# nRF54h20_secure register map
Vendor: Nordic Semiconductor; Series: nRF54h; File version: 1
CPU: CM33 r0p4, little endian, MPU, no FPU, 3 interrupt priority bits, 480 interrupts, 8 SAU regions
Registers are 32-bit, read-write, reset 0x0 unless marked. A register's access mark holds for its fields unless they carry their own. Offsets are from the block's base; [hi:lo] are bit positions; lines under a group give offsets from that group; {n}, {i} and the like mark numbered series; 'fields as' and 'values as' point back to an identical list.

## GLOBAL_UARTE120_NS — UART with EasyDMA 0
Base 0x4F8E6000; alternate view of GLOBAL_SPIM120_NS
Same registers: GLOBAL_UARTE130_NS 0x4F9A5000 (alternate view of GLOBAL_SPIM130_NS), GLOBAL_UARTE131_NS 0x4F9A6000 (alternate view of GLOBAL_SPIM131_NS), GLOBAL_UARTE132_NS 0x4F9B5000 (alternate view of GLOBAL_SPIM132_NS), GLOBAL_UARTE133_NS 0x4F9B6000 (alternate view of GLOBAL_SPIM133_NS), GLOBAL_UARTE134_NS 0x4F9C5000 (alternate view of GLOBAL_SPIM134_NS), GLOBAL_UARTE135_NS 0x4F9C6000 (alternate view of GLOBAL_SPIM135_NS), GLOBAL_UARTE136_NS 0x4F9D5000 (alternate view of GLOBAL_SPIM136_NS), GLOBAL_UARTE137_NS 0x4F9D6000 (alternate view of GLOBAL_SPIM137_NS), GLOBAL_UARTE120_S 0x5F8E6000 (alternate view of GLOBAL_SPIM120_S), GLOBAL_UARTE130_S 0x5F9A5000 (alternate view of GLOBAL_SPIM130_S), GLOBAL_UARTE131_S 0x5F9A6000 (alternate view of GLOBAL_SPIM131_S), GLOBAL_UARTE132_S 0x5F9B5000 (alternate view of GLOBAL_SPIM132_S), GLOBAL_UARTE133_S 0x5F9B6000 (alternate view of GLOBAL_SPIM133_S), GLOBAL_UARTE134_S 0x5F9C5000 (alternate view of GLOBAL_SPIM134_S), GLOBAL_UARTE135_S 0x5F9C6000 (alternate view of GLOBAL_SPIM135_S), GLOBAL_UARTE136_S 0x5F9D5000 (alternate view of GLOBAL_SPIM136_S), GLOBAL_UARTE137_S 0x5F9D6000 (alternate view of GLOBAL_SPIM137_S)
0x0C TASKS_SUSPEND wo — Suspend UART transaction
  [0] TASKS_SUSPEND
    1=Trigger task
0x10 TASKS_RESUME wo — Resume UART transaction
  [0] TASKS_RESUME
    1=Trigger task
0x1C TASKS_FLUSHRX wo — Flush RX FIFO into RX buffer
  [0] TASKS_FLUSHRX
    1=Trigger task
0x28 TASKS_DMA group — Peripheral tasks.
  0x00 RX group — Peripheral tasks.
    0x00 START wo — Starts operation using easyDMA to load the values. See peripheral description for operation using easyDMA.
      [0] START
        1=Trigger task
    0x04 STOP wo — Stops operation using easyDMA. This does not trigger an END event. After a STOP task, the easyDMA (channel) will also enter its lowest required power level.
      [0] STOP
        1=Trigger task
    {0x8+4k} ENABLEMATCH[{k}] (k=0..3) wo — Description collection: Enables the MATCH[n] event by setting the ENABLE[n] bit in the CONFIG register.
      [0] ENABLEMATCH — Enables the MATCH[n] event by setting the ENABLE[n] bit in the CONFIG register.
        1=Trigger task
    {0x18+4k} DISABLEMATCH[{k}] (k=0..3) wo — Description collection: Disables the MATCH[n] event by clearing the ENABLE[n] bit in the CONFIG register.
      [0] DISABLEMATCH — Disables the MATCH[n] event by clearing the ENABLE[n] bit in the CONFIG register.
        1=Trigger task
  0x28 TX group — Peripheral tasks.
    0x00 START wo — Starts operation using easyDMA to load the values. See peripheral description for operation using easyDMA.
      [0] START
        1=Trigger task
    0x04 STOP wo — Stops operation using easyDMA. This does not trigger an END event. After a STOP task, the easyDMA (channel) will also enter its lowest required power level.
      [0] STOP
        1=Trigger task
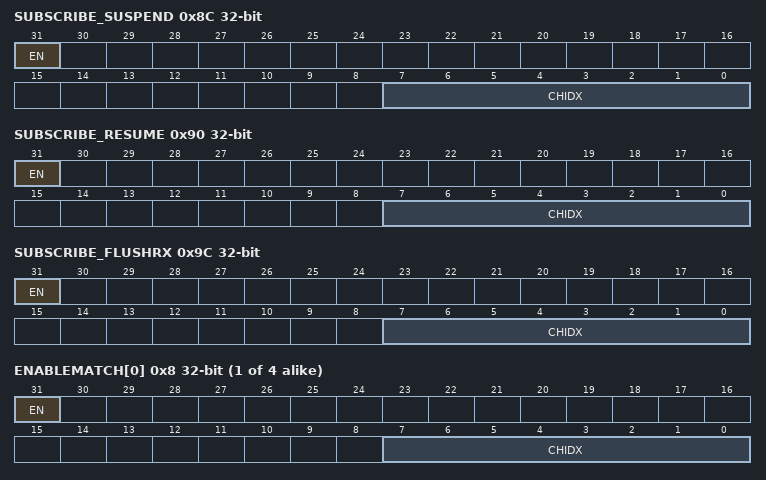
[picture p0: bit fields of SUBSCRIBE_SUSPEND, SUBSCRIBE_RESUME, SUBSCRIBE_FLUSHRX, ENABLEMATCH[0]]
0x8C SUBSCRIBE_SUSPEND — Subscribe configuration for task SUSPEND
  [31] EN
    0=Disabled (Disable subscription); 1=Enabled (Enable subscription)
  [7:0] CHIDX — DPPI channel that task SUSPEND will subscribe to
0x90 SUBSCRIBE_RESUME — Subscribe configuration for task RESUME
  [31] EN
    values as SUBSCRIBE_SUSPEND.EN
  [7:0] CHIDX — DPPI channel that task RESUME will subscribe to
0x9C SUBSCRIBE_FLUSHRX — Subscribe configuration for task FLUSHRX
  [31] EN
    values as SUBSCRIBE_SUSPEND.EN
  [7:0] CHIDX — DPPI channel that task FLUSHRX will subscribe to
0xA8 SUBSCRIBE_DMA group — Subscribe configuration for tasks
  0x00 RX group — Subscribe configuration for tasks
    0x00 START — Subscribe configuration for task START
      [31] EN
        values as SUBSCRIBE_SUSPEND.EN
      [7:0] CHIDX — DPPI channel that task START will subscribe to
    0x04 STOP — Subscribe configuration for task STOP
      [31] EN
        values as SUBSCRIBE_SUSPEND.EN
      [7:0] CHIDX — DPPI channel that task STOP will subscribe to
    {0x8+4k} ENABLEMATCH[{k}] (k=0..3) — Description collection: Subscribe configuration for task ENABLEMATCH[n]
      [31] EN
        values as SUBSCRIBE_SUSPEND.EN
      [7:0] CHIDX — DPPI channel that task ENABLEMATCH[n] will subscribe to
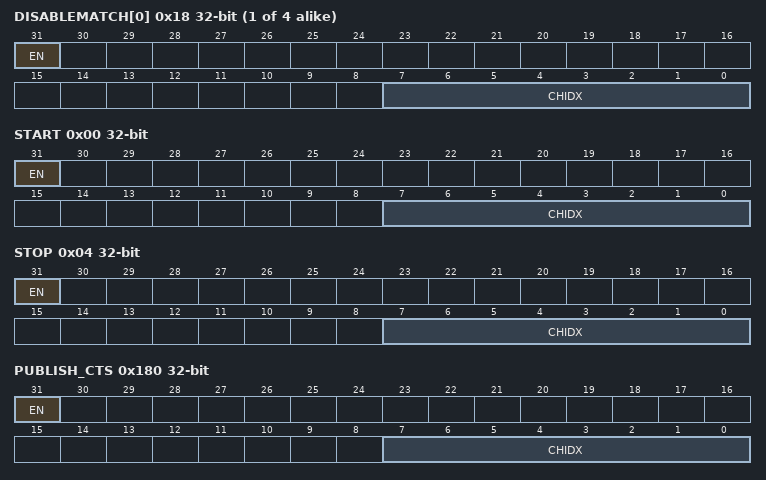
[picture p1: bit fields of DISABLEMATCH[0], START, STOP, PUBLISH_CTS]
    {0x18+4k} DISABLEMATCH[{k}] (k=0..3) — Description collection: Subscribe configuration for task DISABLEMATCH[n]
      [31] EN
        values as SUBSCRIBE_SUSPEND.EN
      [7:0] CHIDX — DPPI channel that task DISABLEMATCH[n] will subscribe to
  0x28 TX group — Subscribe configuration for tasks
    0x00 START — Subscribe configuration for task START
      fields as SUBSCRIBE_DMA.RX.START
    0x04 STOP — Subscribe configuration for task STOP
      fields as SUBSCRIBE_DMA.RX.STOP
0x100 EVENTS_CTS — CTS is activated (set low). Clear To Send.
  [0] EVENTS_CTS
    0=NotGenerated (Event not generated); 1=Generated (Event generated)
0x104 EVENTS_NCTS — CTS is deactivated (set high). Not Clear To Send.
  [0] EVENTS_NCTS
    values as EVENTS_CTS.EVENTS_CTS
0x10C EVENTS_TXDRDY — Data sent from TXD
  [0] EVENTS_TXDRDY
    values as EVENTS_CTS.EVENTS_CTS
0x110 EVENTS_RXDRDY — Data received in RXD (but potentially not yet transferred to Data RAM)
  [0] EVENTS_RXDRDY
    values as EVENTS_CTS.EVENTS_CTS
0x114 EVENTS_ERROR — Error detected
  [0] EVENTS_ERROR
    values as EVENTS_CTS.EVENTS_CTS
0x124 EVENTS_RXTO — Receiver timeout
  [0] EVENTS_RXTO
    values as EVENTS_CTS.EVENTS_CTS
0x12C EVENTS_RTS — RX FIFO has only room for four more bytes before it overflows
  [0] EVENTS_RTS
    values as EVENTS_CTS.EVENTS_CTS
0x130 EVENTS_TXSTOPPED — Transmitter stopped
  [0] EVENTS_TXSTOPPED
    values as EVENTS_CTS.EVENTS_CTS
0x14C EVENTS_DMA group — Peripheral events.
  0x00 RX group — Peripheral events.
    0x00 END — Generated after all MAXCNT bytes have been transferred Equivalent to eventDmaEnd[Channel]
      [0] END
        values as EVENTS_CTS.EVENTS_CTS
    0x04 READY — Generated when EasyDMA has buffered the .PTR and .MAXCNT registers for the channel, allowing them to be written to prepare for the next sequence.
      [0] READY
        values as EVENTS_CTS.EVENTS_CTS
    0x08 BUSERROR — An error occured during the bus transfer. This event is generated on an AHB / AXI error response.
      [0] BUSERROR
        values as EVENTS_CTS.EVENTS_CTS
    {0xC+4k} MATCH[{k}] (k=0..3) — Description collection: Pattern match is detected on the DMA data bus.
      [0] MATCH — Pattern match is detected on the DMA data bus.
        values as EVENTS_CTS.EVENTS_CTS
  0x1C TX group — Peripheral events.
    0x00 END — Generated after all MAXCNT bytes have been transferred Equivalent to eventDmaEnd[Channel]
      fields as EVENTS_DMA.RX.END
    0x04 READY — Generated when EasyDMA has buffered the .PTR and .MAXCNT registers for the channel, allowing them to be written to prepare for the next sequence.
      fields as EVENTS_DMA.RX.READY
    0x08 BUSERROR — An error occured during the bus transfer. This event is generated on an AHB / AXI error response.
      fields as EVENTS_DMA.RX.BUSERROR
0x174 EVENTS_FRAMETIMEOUT — Timed out due to bus being idle while receiving data.
  [0] EVENTS_FRAMETIMEOUT
    values as EVENTS_CTS.EVENTS_CTS
0x180 PUBLISH_CTS — Publish configuration for event CTS
  [31] EN
    0=Disabled (Disable publishing); 1=Enabled (Enable publishing)
  [7:0] CHIDX — DPPI channel that event CTS will publish to
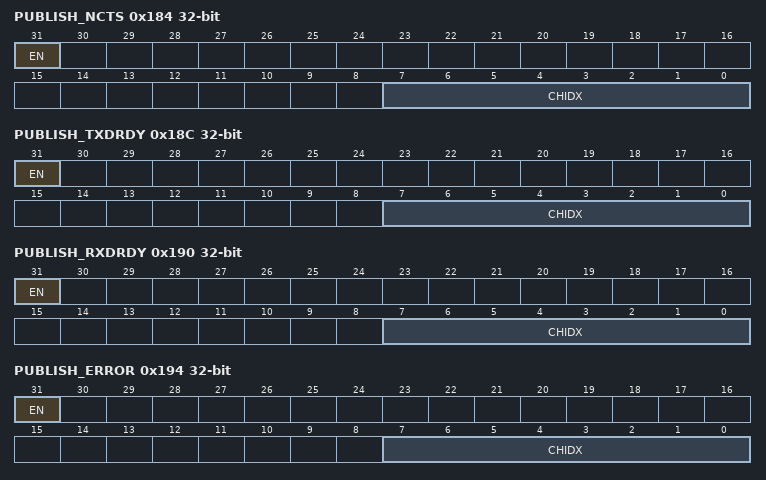
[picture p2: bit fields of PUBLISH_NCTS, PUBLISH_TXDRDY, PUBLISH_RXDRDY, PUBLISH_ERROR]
0x184 PUBLISH_NCTS — Publish configuration for event NCTS
  [31] EN
    values as PUBLISH_CTS.EN
  [7:0] CHIDX — DPPI channel that event NCTS will publish to
0x18C PUBLISH_TXDRDY — Publish configuration for event TXDRDY
  [31] EN
    values as PUBLISH_CTS.EN
  [7:0] CHIDX — DPPI channel that event TXDRDY will publish to
0x190 PUBLISH_RXDRDY — Publish configuration for event RXDRDY
  [31] EN
    values as PUBLISH_CTS.EN
  [7:0] CHIDX — DPPI channel that event RXDRDY will publish to
0x194 PUBLISH_ERROR — Publish configuration for event ERROR
  [31] EN
    values as PUBLISH_CTS.EN
  [7:0] CHIDX — DPPI channel that event ERROR will publish to
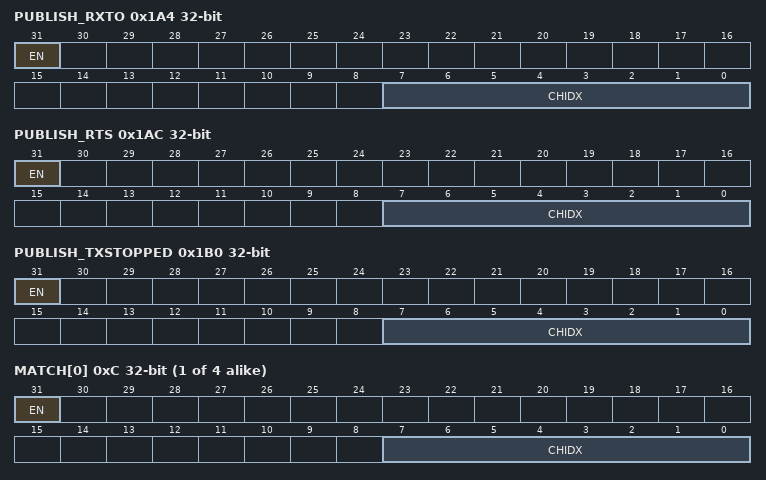
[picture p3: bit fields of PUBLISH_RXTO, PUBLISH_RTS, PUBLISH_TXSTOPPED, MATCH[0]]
0x1A4 PUBLISH_RXTO — Publish configuration for event RXTO
  [31] EN
    values as PUBLISH_CTS.EN
  [7:0] CHIDX — DPPI channel that event RXTO will publish to
0x1AC PUBLISH_RTS — Publish configuration for event RTS
  [31] EN
    values as PUBLISH_CTS.EN
  [7:0] CHIDX — DPPI channel that event RTS will publish to
0x1B0 PUBLISH_TXSTOPPED — Publish configuration for event TXSTOPPED
  [31] EN
    values as PUBLISH_CTS.EN
  [7:0] CHIDX — DPPI channel that event TXSTOPPED will publish to
0x1CC PUBLISH_DMA group — Publish configuration for events
  0x00 RX group — Publish configuration for events
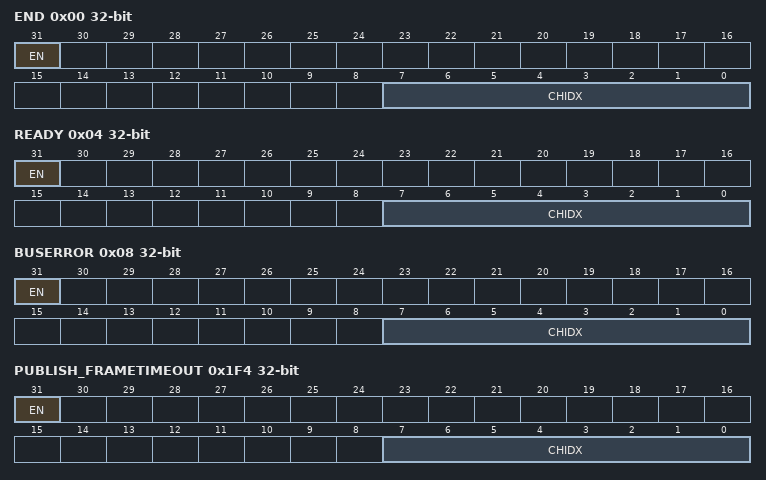
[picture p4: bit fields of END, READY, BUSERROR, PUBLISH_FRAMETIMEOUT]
    0x00 END — Publish configuration for event END
      [31] EN
        values as PUBLISH_CTS.EN
      [7:0] CHIDX — DPPI channel that event END will publish to
    0x04 READY — Publish configuration for event READY
      [31] EN
        values as PUBLISH_CTS.EN
      [7:0] CHIDX — DPPI channel that event READY will publish to
    0x08 BUSERROR — Publish configuration for event BUSERROR
      [31] EN
        values as PUBLISH_CTS.EN
      [7:0] CHIDX — DPPI channel that event BUSERROR will publish to
    {0xC+4k} MATCH[{k}] (k=0..3) — Description collection: Publish configuration for event MATCH[n]
      [31] EN
        values as PUBLISH_CTS.EN
      [7:0] CHIDX — DPPI channel that event MATCH[n] will publish to
  0x1C TX group — Publish configuration for events
    0x00 END — Publish configuration for event END
      fields as PUBLISH_DMA.RX.END
    0x04 READY — Publish configuration for event READY
      fields as PUBLISH_DMA.RX.READY
    0x08 BUSERROR — Publish configuration for event BUSERROR
      fields as PUBLISH_DMA.RX.BUSERROR
0x1F4 PUBLISH_FRAMETIMEOUT — Publish configuration for event FRAMETIMEOUT
  [31] EN
    values as PUBLISH_CTS.EN
  [7:0] CHIDX — DPPI channel that event FRAMETIMEOUT will publish to
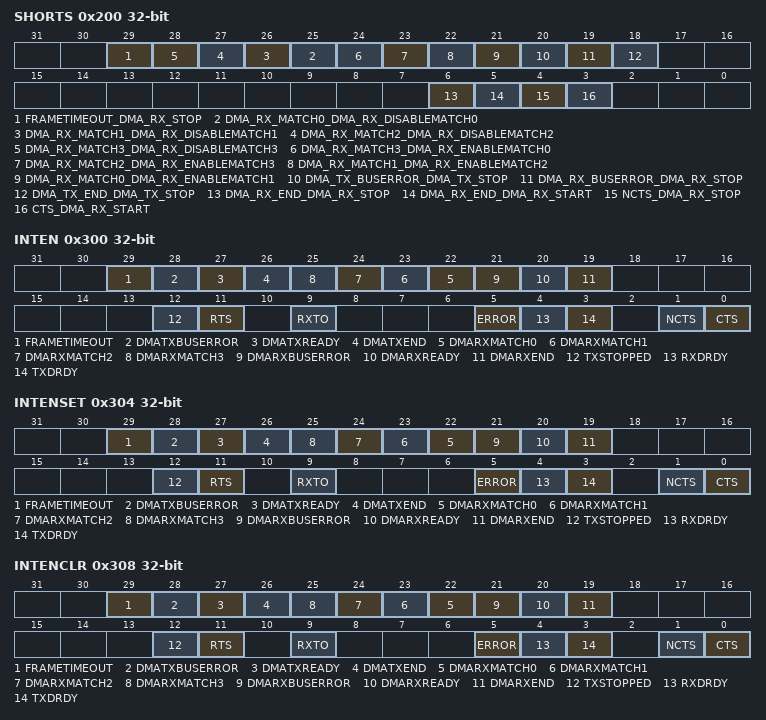
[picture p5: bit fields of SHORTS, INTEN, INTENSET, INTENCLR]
0x200 SHORTS — Shortcuts between local events and tasks
  [all] fields
    0=Disabled (Disable shortcut); 1=Enabled (Enable shortcut)
  [29] FRAMETIMEOUT_DMA_RX_STOP — Shortcut between event FRAMETIMEOUT and task DMA.RX.STOP
  [n+25] DMA_RX_MATCH{n}_DMA_RX_DISABLEMATCH{n} (n=0..3) — Shortcut between event DMA.RX.MATCH[n] and task DMA.RX.DISABLEMATCH[n]
  [24] DMA_RX_MATCH3_DMA_RX_ENABLEMATCH0 — Shortcut between event DMA.RX.MATCH[n] and task DMA.RX.ENABLEMATCH[0] Allows daisy-chaining match events.
  [23] DMA_RX_MATCH2_DMA_RX_ENABLEMATCH3 — Shortcut between event DMA.RX.MATCH[n] and task DMA.RX.ENABLEMATCH[3] Allows daisy-chaining match events.
  [22] DMA_RX_MATCH1_DMA_RX_ENABLEMATCH2 — Shortcut between event DMA.RX.MATCH[n] and task DMA.RX.ENABLEMATCH[2] Allows daisy-chaining match events.
  [21] DMA_RX_MATCH0_DMA_RX_ENABLEMATCH1 — Shortcut between event DMA.RX.MATCH[n] and task DMA.RX.ENABLEMATCH[1] Allows daisy-chaining match events.
  [20] DMA_TX_BUSERROR_DMA_TX_STOP — Shortcut between event DMA.TX.BUSERROR and task DMA.TX.STOP
  [19] DMA_RX_BUSERROR_DMA_RX_STOP — Shortcut between event DMA.RX.BUSERROR and task DMA.RX.STOP
  [18] DMA_TX_END_DMA_TX_STOP — Shortcut between event DMA.TX.END and task DMA.TX.STOP
  [6] DMA_RX_END_DMA_RX_STOP — Shortcut between event DMA.RX.END and task DMA.RX.STOP
  [5] DMA_RX_END_DMA_RX_START — Shortcut between event DMA.RX.END and task DMA.RX.START
  [4] NCTS_DMA_RX_STOP — Shortcut between event NCTS and task DMA.RX.STOP
  [3] CTS_DMA_RX_START — Shortcut between event CTS and task DMA.RX.START
0x300 INTEN — Enable or disable interrupt
  [all] fields
    0=Disabled; 1=Enabled
  [29] FRAMETIMEOUT — Enable or disable interrupt for event FRAMETIMEOUT
  [28] DMATXBUSERROR — Enable or disable interrupt for event DMATXBUSERROR
  [27] DMATXREADY — Enable or disable interrupt for event DMATXREADY
  [26] DMATXEND — Enable or disable interrupt for event DMATXEND
  [n+22] DMARXMATCH{n} (n=0..3) — Enable or disable interrupt for event DMARXMATCH[{n}]
  [21] DMARXBUSERROR — Enable or disable interrupt for event DMARXBUSERROR
  [20] DMARXREADY — Enable or disable interrupt for event DMARXREADY
  [19] DMARXEND — Enable or disable interrupt for event DMARXEND
  [12] TXSTOPPED — Enable or disable interrupt for event TXSTOPPED
  [11] RTS — Enable or disable interrupt for event RTS
  [9] RXTO — Enable or disable interrupt for event RXTO
  [5] ERROR — Enable or disable interrupt for event ERROR
  [4] RXDRDY — Enable or disable interrupt for event RXDRDY
  [3] TXDRDY — Enable or disable interrupt for event TXDRDY
  [1] NCTS — Enable or disable interrupt for event NCTS
  [0] CTS — Enable or disable interrupt for event CTS
0x304 INTENSET — Enable interrupt
  [all] fields
    on read: 0=Disabled (Read: Disabled); 1=Enabled (Read: Enabled) | on write: 1=Set (Enable)
  [29] FRAMETIMEOUT — Write '1' to enable interrupt for event FRAMETIMEOUT
  [28] DMATXBUSERROR — Write '1' to enable interrupt for event DMATXBUSERROR
  [27] DMATXREADY — Write '1' to enable interrupt for event DMATXREADY
  [26] DMATXEND — Write '1' to enable interrupt for event DMATXEND
  [n+22] DMARXMATCH{n} (n=0..3) — Write '1' to enable interrupt for event DMARXMATCH[{n}]
  [21] DMARXBUSERROR — Write '1' to enable interrupt for event DMARXBUSERROR
  [20] DMARXREADY — Write '1' to enable interrupt for event DMARXREADY
  [19] DMARXEND — Write '1' to enable interrupt for event DMARXEND
  [12] TXSTOPPED — Write '1' to enable interrupt for event TXSTOPPED
  [11] RTS — Write '1' to enable interrupt for event RTS
  [9] RXTO — Write '1' to enable interrupt for event RXTO
  [5] ERROR — Write '1' to enable interrupt for event ERROR
  [4] RXDRDY — Write '1' to enable interrupt for event RXDRDY
  [3] TXDRDY — Write '1' to enable interrupt for event TXDRDY
  [1] NCTS — Write '1' to enable interrupt for event NCTS
  [0] CTS — Write '1' to enable interrupt for event CTS
0x308 INTENCLR — Disable interrupt
  [all] fields
    on read: 0=Disabled (Read: Disabled); 1=Enabled (Read: Enabled) | on write: 1=Clear (Disable)
  [29] FRAMETIMEOUT — Write '1' to disable interrupt for event FRAMETIMEOUT
  [28] DMATXBUSERROR — Write '1' to disable interrupt for event DMATXBUSERROR
  [27] DMATXREADY — Write '1' to disable interrupt for event DMATXREADY
  [26] DMATXEND — Write '1' to disable interrupt for event DMATXEND
  [n+22] DMARXMATCH{n} (n=0..3) — Write '1' to disable interrupt for event DMARXMATCH[{n}]
  [21] DMARXBUSERROR — Write '1' to disable interrupt for event DMARXBUSERROR
  [20] DMARXREADY — Write '1' to disable interrupt for event DMARXREADY
  [19] DMARXEND — Write '1' to disable interrupt for event DMARXEND
  [12] TXSTOPPED — Write '1' to disable interrupt for event TXSTOPPED
  [11] RTS — Write '1' to disable interrupt for event RTS
  [9] RXTO — Write '1' to disable interrupt for event RXTO
  [5] ERROR — Write '1' to disable interrupt for event ERROR
  [4] RXDRDY — Write '1' to disable interrupt for event RXDRDY
  [3] TXDRDY — Write '1' to disable interrupt for event TXDRDY
  [1] NCTS — Write '1' to disable interrupt for event NCTS
  [0] CTS — Write '1' to disable interrupt for event CTS
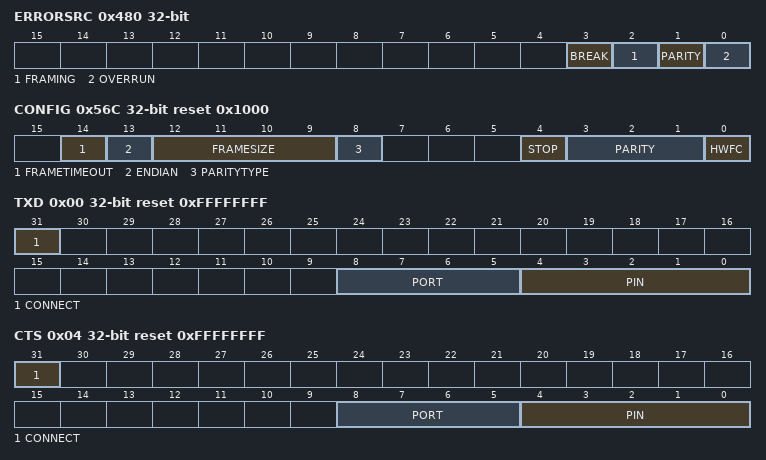
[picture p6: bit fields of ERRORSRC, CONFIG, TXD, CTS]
0x480 ERRORSRC write-1-clears — Error source
  [all] fields
    on read: 0=NotPresent (Read: error not present); 1=Present (Read: error present)
  [3] BREAK — Break condition
  [2] FRAMING — Framing error occurred
  [1] PARITY — Parity error
  [0] OVERRUN — Overrun error
0x500 ENABLE — Enable UART
  [3:0] ENABLE — Enable or disable UARTE
    0=Disabled (Disable UARTE); 8=Enabled (Enable UARTE)
0x524 BAUDRATE reset 0x4000000 — Baud rate. Accuracy depends on the HFCLK source selected.
  [31:0] BAUDRATE
    0x4F000=Baud1200 (1200 baud (actual rate: 1205) when UARTE has 16 MHz peripheral clock frequency); 0x9D000=Baud2400 (2400 baud (actual rate: 2396) when UARTE has 16 MHz peripheral clock frequency); 0x13B000=Baud4800 (4800 baud (actual rate: 4808) when UARTE has 16 MHz peripheral clock frequency); 0x275000=Baud9600 (9600 baud (actual rate: 9598) when UARTE has 16 MHz peripheral clock frequency); 0x3AF000=Baud14400 (14400 baud (actual rate: 14401) when UARTE has 16 MHz peripheral clock frequency); 0x4EA000=Baud19200 (19200 baud (actual rate: 19208) when UARTE has 16 MHz peripheral clock frequency); 0x75C000=Baud28800 (28800 baud (actual rate: 28777) when UARTE has 16 MHz peripheral clock frequency); 0x800000=Baud31250 (31250 baud when UARTE has 16 MHz peripheral clock frequency); 0x9D0000=Baud38400 (38400 baud (actual rate: 38369) when UARTE has 16 MHz peripheral clock frequency); 0xE50000=Baud56000 (56000 baud (actual rate: 55944) when UARTE has 16 MHz peripheral clock frequency); 0xEB0000=Baud57600 (57600 baud (actual rate: 57554) when UARTE has 16 MHz peripheral clock frequency); 0x13A9000=Baud76800 (76800 baud (actual rate: 76923) when UARTE has 16 MHz peripheral clock frequency); 0x1D60000=Baud115200 (115200 baud (actual rate: 115108) when UARTE has 16 MHz peripheral clock frequency); 0x3B00000=Baud230400 (230400 baud (actual rate: 231884) when UARTE has 16 MHz peripheral clock frequency); 0x4000000=Baud250000 (250000 baud when UARTE has 16 MHz peripheral clock frequency); 0x7400000=Baud460800 (460800 baud (actual rate: 457143) when UARTE has 16 MHz peripheral clock frequency); 0xF000000=Baud921600 (921600 baud (actual rate: 941176) when UARTE has 16 MHz peripheral clock frequency); 0x10000000=Baud1M (1 megabaud when UARTE has 16 MHz peripheral clock frequency)
0x56C CONFIG reset 0x1000 — Configuration of parity, hardware flow control, framesize, and packet timeout.
  [14] FRAMETIMEOUT — Enable packet timeout.
    0=DISABLED (Packet timeout is disabled.); 1=ENABLED (Packet timeout is enabled.); 0=Disabled (Packet timeout is disabled.); 1=Enabled (Packet timeout is enabled.)
  [13] ENDIAN — Select if data is trimmed from MSB or LSB end when the data frame size is less than 8.
    0=MSB (Data is trimmed from MSB end.); 1=LSB (Data is trimmed from LSB end.)
  [12:9] FRAMESIZE — Set the data frame size
    9=9 bit data frame size. 9th bit is treated as address bit.; {v}={v} bit data frame size (v=4..8)
  [8] PARITYTYPE — Even or odd parity type
    0=Even parity; 1=Odd (Odd parity)
  [4] STOP — Stop bits
    0=One (One stop bit); 1=Two (Two stop bits)
  [3:1] PARITY
    0=Excluded (Exclude parity bit); 7=Included (Include even parity bit)
  [0] HWFC — Hardware flow control
    0=Disabled; 1=Enabled
0x574 ADDRESS — Set the address of the UARTE for RX when used in 9 bit data frame mode.
  [7:0] ADDRESS — Set address
0x578 FRAMETIMEOUT reset 0x10 — Set the number of UARTE bits to count before triggering packet timeout.
  [9:0] COUNTERTOP — Number of UARTE bits before timeout.
0x604 PSEL group — Unspecified
  0x00 TXD reset 0xFFFFFFFF — Pin select for TXD signal
    [31] CONNECT — Connection
      1=Disconnected; 0=Connected
    [8:5] PORT — Port number
    [4:0] PIN — Pin number
  0x04 CTS reset 0xFFFFFFFF — Pin select for CTS signal
    fields as PSEL.TXD
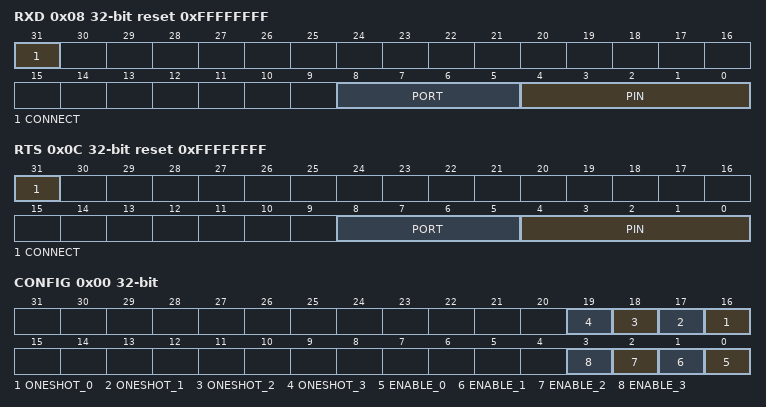
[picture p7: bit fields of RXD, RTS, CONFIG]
  0x08 RXD reset 0xFFFFFFFF — Pin select for RXD signal
    fields as PSEL.TXD
  0x0C RTS reset 0xFFFFFFFF — Pin select for RTS signal
    fields as PSEL.TXD
0x700 DMA group — Unspecified
  0x00 RX group — Unspecified
    0x00 ENABLE — Register doesn't do anything. Can be written and read, but has no functionality attached.
      [0] ENABLE
        0=Disabled; 1=Enabled
    0x04 PTR — RAM buffer start address
      [31:0] PTR — RAM buffer start address for this EasyDMA channel. This address is a word aligned Data RAM address.
    0x08 MAXCNT — Maximum number of bytes in channel buffer
      [15:0] MAXCNT
    0x0C AMOUNT ro — Number of bytes transferred in the last transaction, updated after the END event. Also updated after each MATCH event.
      [15:0] AMOUNT — Number of bytes transferred in the last transaction. In case of NACK error, includes the NACK'ed byte.
    0x10 CURRENTAMOUNT ro — Number of bytes transferred in the current transaction
      [15:0] AMOUNT — Number of bytes transferred in the current transaction. Continuously updated. Updated when data leaves the internal FIFO and is transferred to the destination.
    0x14 LIST — EasyDMA list type
      [2:0] TYPE — List type
        0=Disabled (Disable EasyDMA list); 1=ArrayList (Use array list)
    0x1C TERMINATEONBUSERROR — Terminate the transaction if a BUSERROR event is detected.
      [0] ENABLE
        0=Disabled; 1=Enabled
    0x20 BUSERRORADDRESS ro — Address of transaction that generated the last BUSERROR event.
      [31:0] ADDRESS
    0x24 MATCH group — Registers to control the behavior of the pattern matcher engine
      0x00 CONFIG — Configure individual match events
        [n+16] ONESHOT_{n} (n=0..3) — Configure match filter {n} as one-shot or continous
          0=Continuous (Match filter stays enabled until disabled by task); 1=Oneshot (Match filter stays enabled until next data word is received)
        [n] ENABLE_{n} (n=0..3) — Enable match filter {n}
          0=Disabled (Match filter disabled); 1=Enabled (Match filter enabled)
      {0x4+4l} CANDIDATE[{l}] (l=0..3) — Description collection: The data to look for - any match will trigger the MATCH[n] event, if enabled.
        [7:0] DATA — Data to look for
  0x38 TX group — Unspecified
    0x00 ENABLE — Register doesn't do anything. Can be written and read, but has no functionality attached.
      [0] ENABLE
        0=Disabled; 1=Enabled
    0x04 PTR — RAM buffer start address
      fields as DMA.RX.PTR
    0x08 MAXCNT — Maximum number of bytes in channel buffer
      [15:0] MAXCNT
    0x0C AMOUNT ro — Number of bytes transferred in the last transaction, updated after the END event. Also updated after each MATCH event.
      fields as DMA.RX.AMOUNT
    0x10 CURRENTAMOUNT ro — Number of bytes transferred in the current transaction
      fields as DMA.RX.CURRENTAMOUNT
    0x14 LIST — EasyDMA list type
      fields as DMA.RX.LIST
    0x1C TERMINATEONBUSERROR — Terminate the transaction if a BUSERROR event is detected.
      [0] ENABLE
        0=Disabled; 1=Enabled
    0x20 BUSERRORADDRESS ro — Address of transaction that generated the last BUSERROR event.
      [31:0] ADDRESS

## Notices in the file
Copyright (c) 2010 - 2025, Nordic Semiconductor ASA
All rights reserved.
Redistribution and use in source and binary forms, with or without modification,
are permitted provided that the following conditions are met:
1. Redistributions of source code must retain the above copyright notice, this
list of conditions and the following disclaimer.
2. Redistributions in binary form, except as embedded into a Nordic
Semiconductor ASA integrated circuit in a product or a software update for
such product, must reproduce the above copyright notice, this list of
conditions and the following disclaimer in the documentation and/or other
materials provided with the distribution.
3. Neither the name of Nordic Semiconductor ASA nor the names of its
contributors may be used to endorse or promote products derived from this
software without specific prior written permission.
4. This software, with or without modification, must only be used with a
Nordic Semiconductor ASA integrated circuit.
5. Any software provided in binary form under this license must not be reverse
engineered, decompiled, modified and/or disassembled.
THIS SOFTWARE IS PROVIDED BY NORDIC SEMICONDUCTOR ASA "AS IS" AND ANY EXPRESS
OR IMPLIED WARRANTIES, INCLUDING, BUT NOT LIMITED TO, THE IMPLIED WARRANTIES
OF MERCHANTABILITY, NONINFRINGEMENT, AND FITNESS FOR A PARTICULAR PURPOSE ARE
DISCLAIMED. IN NO EVENT SHALL NORDIC SEMICONDUCTOR ASA OR CONTRIBUTORS BE
LIABLE FOR ANY DIRECT, INDIRECT, INCIDENTAL, SPECIAL, EXEMPLARY, OR
CONSEQUENTIAL DAMAGES (INCLUDING, BUT NOT LIMITED TO, PROCUREMENT OF SUBSTITUTE
GOODS OR SERVICES; LOSS OF USE, DATA, OR PROFITS; OR BUSINESS INTERRUPTION)
HOWEVER CAUSED AND ON ANY THEORY OF LIABILITY, WHETHER IN CONTRACT, STRICT
LIABILITY, OR TORT (INCLUDING NEGLIGENCE OR OTHERWISE) ARISING IN ANY WAY OUT
OF THE USE OF THIS SOFTWARE, EVEN IF ADVISED OF THE POSSIBILITY OF SUCH DAMAGE.
